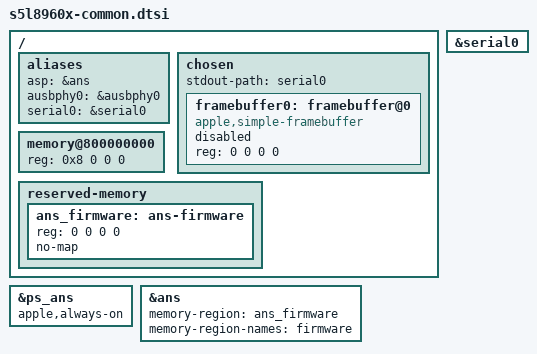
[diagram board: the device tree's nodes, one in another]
// SPDX-License-Identifier: GPL-2.0+ OR MIT
/*
 * Apple iPhone 5s, iPad mini 2/3, iPad Air
 *
 * This file contains parts common to all Apple A7 devices.
 *
 * target-type: J71, J72, J73, J85, J85m, J86, J86m, J87, J87m, N51, N53
 *
 * Copyright (c) 2024, Nick Chan <towinchenmi@gmail.com>
 */

/ {
	aliases {
		asp = &ans; /* Used by loader */
		ausbphy0 = &ausbphy0; /* Used by loader */
		serial0 = &serial0;
	};

	chosen {
		#address-cells = <2>;
		#size-cells = <2>;
		ranges;

		stdout-path = "serial0";

		framebuffer0: framebuffer@0 {
			compatible = "apple,simple-framebuffer", "simple-framebuffer";
			reg = <0 0 0 0>; /* To be filled by loader */
			/* Format properties will be added by loader */
			status = "disabled";
		};
	};

	memory@800000000 {
		device_type = "memory";
		reg = <0x8 0 0 0>; /* To be filled by loader */
	};

	reserved-memory {
		#address-cells = <2>;
		#size-cells = <2>;
		ranges;

		/* To be filled by loader */

		ans_firmware: ans-firmware {
			/* Filled in by the loader. */
			reg = <0 0 0 0>;
			no-map;
		};
	};
};

&serial0 {
	status = "okay";
};

/*
 * Internal storage: the ANS (Apple's iop,s5l8960x with an rtbuddy nub), at
 * the same address with the same interrupts in the device tree of every A7
 * board. The loader fills in its firmware region from the ADT.
 */
&ps_ans {
	apple,always-on;
};

&ans {
	memory-region = <&ans_firmware>;
	memory-region-names = "firmware";
	status = "okay";
};
